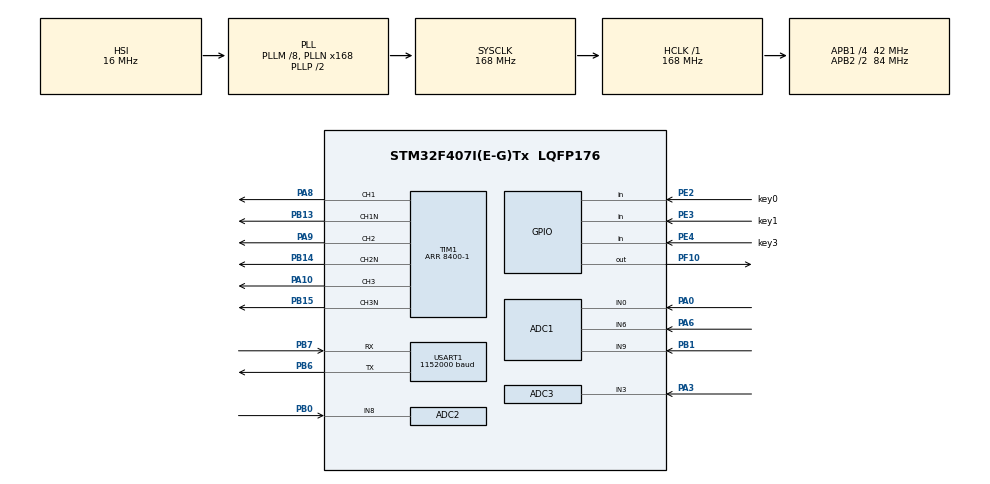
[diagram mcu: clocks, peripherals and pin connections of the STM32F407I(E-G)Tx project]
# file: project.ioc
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ADC1.Channel-0\#ChannelRegularConversion=ADC_CHANNEL_0
ADC1.Channel-1\#ChannelInjectedConversion=ADC_CHANNEL_6
ADC1.Channel-2\#ChannelRegularConversion=ADC_CHANNEL_9
ADC1.ContinuousConvMode=ENABLE
ADC1.DMAContinuousRequests=ENABLE
ADC1.ExternalTrigInjecConv=ADC_EXTERNALTRIGINJECCONV_T1_CC4
ADC1.InjNumberOfConversion=1
ADC1.InjectedOffset-1\#ChannelInjectedConversion=0
ADC1.InjectedRank-1\#ChannelInjectedConversion=1
ADC1.Mode=ADC_TRIPLEMODE_INJECSIMULT
ADC1.NbrOfConversion=2
ADC1.NbrOfConversionFlag=1
ADC1.Rank-0\#ChannelRegularConversion=1
ADC1.Rank-2\#ChannelRegularConversion=2
ADC1.SamplingTime-0\#ChannelRegularConversion=ADC_SAMPLETIME_84CYCLES
ADC1.SamplingTime-1\#ChannelInjectedConversion=ADC_SAMPLETIME_3CYCLES
ADC1.SamplingTime-2\#ChannelRegularConversion=ADC_SAMPLETIME_84CYCLES
ADC1.ScanConvMode=ENABLE
ADC1.master=1
ADC2.Channel-0\#ChannelRegularConversion=ADC_CHANNEL_8
ADC2.Channel-2\#ChannelInjectedConversion=ADC_CHANNEL_8
ADC2.InjNumberOfConversion=1
ADC2.InjectedOffset-2\#ChannelInjectedConversion=0
ADC2.InjectedRank-2\#ChannelInjectedConversion=1
ADC2.Mode=ADC_TRIPLEMODE_INJECSIMULT
ADC2.NbrOfConversionFlag=1
ADC2.Rank-0\#ChannelRegularConversion=1
ADC2.SamplingTime-0\#ChannelRegularConversion=ADC_SAMPLETIME_3CYCLES
ADC2.SamplingTime-2\#ChannelInjectedConversion=ADC_SAMPLETIME_3CYCLES
ADC2.ScanConvMode=ENABLE
ADC3.Channel-0\#ChannelRegularConversion=ADC_CHANNEL_3
ADC3.Channel-2\#ChannelInjectedConversion=ADC_CHANNEL_3
ADC3.ContinuousConvMode=ENABLE
ADC3.InjNumberOfConversion=1
ADC3.InjectedOffset-2\#ChannelInjectedConversion=0
ADC3.InjectedRank-2\#ChannelInjectedConversion=1
ADC3.Mode=ADC_TRIPLEMODE_INJECSIMULT
ADC3.NbrOfConversion=1
ADC3.NbrOfConversionFlag=1
ADC3.Rank-0\#ChannelRegularConversion=1
ADC3.SamplingTime-0\#ChannelRegularConversion=ADC_SAMPLETIME_3CYCLES
ADC3.SamplingTime-2\#ChannelInjectedConversion=ADC_SAMPLETIME_3CYCLES
ADC3.ScanConvMode=ENABLE
Dma.ADC1.0.Direction=DMA_PERIPH_TO_MEMORY
Dma.ADC1.0.FIFOMode=DMA_FIFOMODE_DISABLE
Dma.ADC1.0.Instance=DMA2_Stream0
Dma.ADC1.0.MemDataAlignment=DMA_MDATAALIGN_HALFWORD
Dma.ADC1.0.MemInc=DMA_MINC_ENABLE
Dma.ADC1.0.Mode=DMA_CIRCULAR
Dma.ADC1.0.PeriphDataAlignment=DMA_PDATAALIGN_HALFWORD
Dma.ADC1.0.PeriphInc=DMA_PINC_DISABLE
Dma.ADC1.0.Priority=DMA_PRIORITY_LOW
Dma.Request0=ADC1
Mcu.Family=STM32F4
Mcu.Name=STM32F407I(E-G)Tx
Mcu.Package=LQFP176
NVIC.ADC_IRQn=true\:1\:0\:true\:false\:true\:true\:true\:true
NVIC.DMA2_Stream0_IRQn=true\:2\:0\:true\:false\:true\:false\:true\:true
NVIC.PriorityGroup=NVIC_PRIORITYGROUP_4
PA0-WKUP.Signal=ADCx_IN0
PA10.Signal=S_TIM1_CH3
PA3.Signal=ADCx_IN3
PA6.Signal=ADCx_IN6
PA8.Signal=S_TIM1_CH1
PA9.Signal=S_TIM1_CH2
PB0.Signal=ADCx_IN8
PB1.Signal=ADCx_IN9
PB13.Mode=PWM Generation1 CH1 CH1N
PB13.Signal=TIM1_CH1N
PB14.Mode=PWM Generation2 CH2 CH2N
PB14.Signal=TIM1_CH2N
PB15.Mode=PWM Generation3 CH3 CH3N
PB15.Signal=TIM1_CH3N
PB6.Mode=Asynchronous
PB6.Signal=USART1_TX
PB7.Mode=Asynchronous
PB7.Signal=USART1_RX
PE2.GPIO_Label=key0
PE2.GPIO_PuPd=GPIO_PULLUP
PE2.Signal=GPIO_Input
PE3.GPIO_Label=key1
PE3.GPIO_PuPd=GPIO_PULLUP
PE3.Signal=GPIO_Input
PE4.GPIO_Label=key3
PE4.GPIO_PuPd=GPIO_PULLUP
PE4.Signal=GPIO_Input
PF10.PinState=GPIO_PIN_SET
PF10.Signal=GPIO_Output
PH0-OSC_IN.Mode=HSE-External-Oscillator
PH0-OSC_IN.Signal=RCC_OSC_IN
PH1-OSC_OUT.Mode=HSE-External-Oscillator
PH1-OSC_OUT.Signal=RCC_OSC_OUT
ProjectManager.HeapSize=0x200
ProjectManager.StackSize=0x400
ProjectManager.TargetToolchain=CMake
RCC.48MHZClocksFreq_Value=84000000
RCC.AHBFreq_Value=168000000
RCC.APB1CLKDivider=RCC_HCLK_DIV4
RCC.APB1Freq_Value=42000000
RCC.APB1TimFreq_Value=84000000
RCC.APB2CLKDivider=RCC_HCLK_DIV2
RCC.APB2Freq_Value=84000000
RCC.APB2TimFreq_Value=168000000
RCC.CortexFreq_Value=168000000
RCC.HCLKFreq_Value=168000000
RCC.HSE_VALUE=25000000
RCC.HSI_VALUE=16000000
RCC.LSE_VALUE=32768
RCC.PLLM=8
RCC.PLLN=168
RCC.SYSCLKFreq_VALUE=168000000
RCC.SYSCLKSource=RCC_SYSCLKSOURCE_PLLCLK
RCC.VCOOutputFreq_Value=336000000
SH.ADCx_IN0.0=ADC1_IN0,IN0
SH.ADCx_IN3.0=ADC3_IN3,IN3
SH.ADCx_IN6.0=ADC1_IN6,IN6
SH.ADCx_IN8.0=ADC2_IN8,IN8
SH.ADCx_IN9.0=ADC1_IN9,IN9
SH.S_TIM1_CH1.0=TIM1_CH1,PWM Generation1 CH1 CH1N
SH.S_TIM1_CH2.0=TIM1_CH2,PWM Generation2 CH2 CH2N
SH.S_TIM1_CH3.0=TIM1_CH3,PWM Generation3 CH3 CH3N
TIM1.AutomaticOutput=TIM_AUTOMATICOUTPUT_ENABLE
TIM1.Channel-PWM\ Generation1\ CH1\ CH1N=TIM_CHANNEL_1
TIM1.Channel-PWM\ Generation2\ CH2\ CH2N=TIM_CHANNEL_2
TIM1.Channel-PWM\ Generation3\ CH3\ CH3N=TIM_CHANNEL_3
TIM1.Channel-PWM\ Generation4\ No\ Output=TIM_CHANNEL_4
TIM1.CounterMode=TIM_COUNTERMODE_CENTERALIGNED1
TIM1.DeadTime=100
TIM1.Period=8400-1
TIM1.Pulse-PWM\ Generation4\ No\ Output=8390
USART1.BaudRate=1152000
USART1.VirtualMode=VM_ASYNC
VP_TIM1_VS_no_output4.Mode=PWM Generation4 No Output
board=custom

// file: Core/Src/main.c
/* USER CODE BEGIN Header */
/**
  ******************************************************************************
  * @file           : main.c
  * @brief          : Main program body
  ******************************************************************************
  * @attention
  *
  * Copyright (c) 2026 STMicroelectronics.
  * All rights reserved.
  *
  * This software is licensed under terms that can be found in the LICENSE file
  * in the root directory of this software component.
  * If no LICENSE file comes with this software, it is provided AS-IS.
  *
  ******************************************************************************
  */
/* USER CODE END Header */
#include "main.h"
#include "adc.h"
#include "dma.h"
#include "tim.h"
#include "usart.h"
#include "gpio.h"

/* USER CODE BEGIN Includes */
#include "key.h"
/* USER CODE END Includes */

void SystemClock_Config(void);

int main(void)
{

  /* MCU Configuration--------------------------------------------------------*/

  /* Reset of all peripherals, Initializes the Flash interface and the Systick. */
  HAL_Init();

  /* Configure the system clock */
  SystemClock_Config();

  /* Initialize all configured peripherals */
  MX_GPIO_Init();
  MX_DMA_Init();
  MX_TIM1_Init();
  MX_ADC1_Init();
  MX_ADC2_Init();
  MX_ADC3_Init();
  MX_USART1_UART_Init();
  /* USER CODE BEGIN 2 */

  Motor_Init();

  /* USER CODE END 2 */

  /* Infinite loop */
  /* USER CODE BEGIN WHILE */
  while (1)
  {

	uint8_t key=key_scan();
    if(key==key0)
       {
        HAL_GPIO_TogglePin(GPIOF, GPIO_PIN_10);
       }
    else if(key==key1)
    {
      Motor_Toggle();
    }
      else if(key==key2)
    {
	  }

   printf("%.2f,%.2f,%.2f,%.2f,%.2f,%.2f\r\n",rtX.Id_ref,rtX.Iq_ref,Current_Id_Iq.Id,Current_Id_Iq.Iq,Voltage_DQ.Vd,Voltage_DQ.Vq);

    /* USER CODE END WHILE */

  }
}

void SystemClock_Config(void)
{
  RCC_OscInitTypeDef RCC_OscInitStruct = {0};
  RCC_ClkInitTypeDef RCC_ClkInitStruct = {0};

  /** Configure the main internal regulator output voltage
  */
  __HAL_RCC_PWR_CLK_ENABLE();
  __HAL_PWR_VOLTAGESCALING_CONFIG(PWR_REGULATOR_VOLTAGE_SCALE1);

  /** Initializes the RCC Oscillators according to the specified parameters
  * in the RCC_OscInitTypeDef structure.
  */
  RCC_OscInitStruct.OscillatorType = RCC_OSCILLATORTYPE_HSI;
  RCC_OscInitStruct.HSIState = RCC_HSI_ON;
  RCC_OscInitStruct.HSICalibrationValue = RCC_HSICALIBRATION_DEFAULT;
  RCC_OscInitStruct.PLL.PLLState = RCC_PLL_ON;
  RCC_OscInitStruct.PLL.PLLSource = RCC_PLLSOURCE_HSI;
  RCC_OscInitStruct.PLL.PLLM = 8;
  RCC_OscInitStruct.PLL.PLLN = 168;
  RCC_OscInitStruct.PLL.PLLP = RCC_PLLP_DIV2;
  RCC_OscInitStruct.PLL.PLLQ = 4;
  if (HAL_RCC_OscConfig(&RCC_OscInitStruct) != HAL_OK)
  {
    Error_Handler();
  }

  /** Initializes the CPU, AHB and APB buses clocks
  */
  RCC_ClkInitStruct.ClockType = RCC_CLOCKTYPE_HCLK|RCC_CLOCKTYPE_SYSCLK
                              |RCC_CLOCKTYPE_PCLK1|RCC_CLOCKTYPE_PCLK2;
  RCC_ClkInitStruct.SYSCLKSource = RCC_SYSCLKSOURCE_PLLCLK;
  RCC_ClkInitStruct.AHBCLKDivider = RCC_SYSCLK_DIV1;
  RCC_ClkInitStruct.APB1CLKDivider = RCC_HCLK_DIV4;
  RCC_ClkInitStruct.APB2CLKDivider = RCC_HCLK_DIV2;

  if (HAL_RCC_ClockConfig(&RCC_ClkInitStruct, FLASH_LATENCY_5) != HAL_OK)
  {
    Error_Handler();
  }
}

void Error_Handler(void)
{
  __disable_irq();
  while (1)
  {
  }
}
